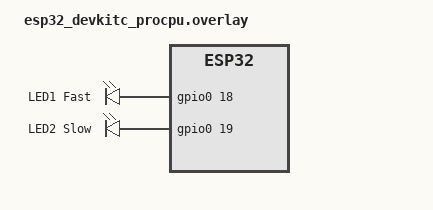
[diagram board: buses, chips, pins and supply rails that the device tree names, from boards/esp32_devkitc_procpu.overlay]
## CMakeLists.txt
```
cmake_minimum_required(VERSION 3.20.0)

find_package(Zephyr REQUIRED HINTS $ENV{ZEPHYR_BASE})
project(two_threads_led)

target_sources(app PRIVATE src/main.c)
```

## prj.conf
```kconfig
# GPIO support
CONFIG_GPIO=y

# Console output
CONFIG_CONSOLE=y
CONFIG_PRINTK=y
```

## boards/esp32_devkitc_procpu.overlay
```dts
#include <zephyr/dt-bindings/gpio/gpio.h>

/ {
    aliases {
        led1 = &fast_led;
        led2 = &slow_led;
    };

    leds {
        compatible = "gpio-leds";

        fast_led: led_0 {
            gpios = <&gpio0 18 GPIO_ACTIVE_HIGH>;
            label = "LED1 Fast";
        };

        slow_led: led_1 {
            gpios = <&gpio0 19 GPIO_ACTIVE_HIGH>;
            label = "LED2 Slow";
        };
    };
};
```

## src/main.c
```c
#include <zephyr/kernel.h>
#include <zephyr/drivers/gpio.h>
#include <zephyr/sys/printk.h>

#define STACK_SIZE 2048
#define THREAD_PRIORITY 7

#define FAST_INTERVAL_MS 200
#define SLOW_INTERVAL_MS 1000

/* Devicetree LED definitions */
static const struct gpio_dt_spec led1 =
    GPIO_DT_SPEC_GET(DT_ALIAS(led1), gpios);

static const struct gpio_dt_spec led2 =
    GPIO_DT_SPEC_GET(DT_ALIAS(led2), gpios);

/* Thread 1 - fast blinking */
static void blink_fast(void *arg1, void *arg2, void *arg3)
{
    ARG_UNUSED(arg1);
    ARG_UNUSED(arg2);
    ARG_UNUSED(arg3);

    if (!gpio_is_ready_dt(&led1) ||
        gpio_pin_configure_dt(&led1, GPIO_OUTPUT_INACTIVE) < 0) {
        printk("LED1 initialization failed\n");
        return;
    }

    while (true) {
        gpio_pin_toggle_dt(&led1);
        k_msleep(FAST_INTERVAL_MS);
    }
}

/* Thread 2 - slow blinking */
static void blink_slow(void *arg1, void *arg2, void *arg3)
{
    ARG_UNUSED(arg1);
    ARG_UNUSED(arg2);
    ARG_UNUSED(arg3);

    if (!gpio_is_ready_dt(&led2) ||
        gpio_pin_configure_dt(&led2, GPIO_OUTPUT_INACTIVE) < 0) {
        printk("LED2 initialization failed\n");
        return;
    }

    while (true) {
        gpio_pin_toggle_dt(&led2);
        k_msleep(SLOW_INTERVAL_MS);
    }
}

/* Thread creation */
K_THREAD_DEFINE(thread1_id, STACK_SIZE, blink_fast,
                NULL, NULL, NULL, THREAD_PRIORITY, 0, 0);

K_THREAD_DEFINE(thread2_id, STACK_SIZE, blink_slow,
                NULL, NULL, NULL, THREAD_PRIORITY, 0, 0);

int main(void)
{
    printk("Two Threads / Two LEDs\n");

    return 0;
}
```
